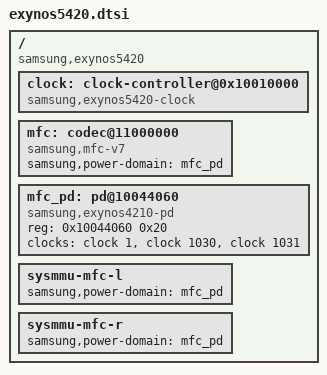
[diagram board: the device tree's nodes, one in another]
/*
 * Google Peach Pit board device tree source
 *
 * Copyright (c) 2013 Google, Inc
 *
 * This program is free software; you can redistribute it and/or modify
 * it under the terms of the GNU General Public License version 2 as
 * published by the Free Software Foundation.
 */

#include "exynos542x.dtsi"

/ {

	compatible = "samsung,exynos5420";

	clock: clock-controller@0x10010000 {
		compatible = "samsung,exynos5420-clock";
	};

	mfc: codec@11000000 {
		compatible = "samsung,mfc-v7";
	};

	/* TEMPORARILY MOVED FROM exynos542x.dtsi */
	mfc_pd: pd@10044060 {
		compatible = "samsung,exynos4210-pd";
		reg = <0x10044060 0x20>;
		clocks = <&clock 1>, <&clock 1030>, <&clock 1031>;
		clock-names = "oscclk", "pclk0", "clk0";
	};

	mfc: codec@11000000 {
		samsung,power-domain = <&mfc_pd>;
	};

	sysmmu-mfc-l {
		samsung,power-domain = <&mfc_pd>;
	};

	sysmmu-mfc-r {
		samsung,power-domain = <&mfc_pd>;
	};
	/* END TEMPORARY MOVE */
};
